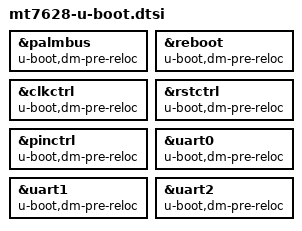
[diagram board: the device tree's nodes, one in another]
// SPDX-License-Identifier: GPL-2.0
/*
 * Copyright (C) 2020 MediaTek Inc.
 *
 * Author: Weijie Gao <weijie.gao@mediatek.com>
 */

&palmbus {
	u-boot,dm-pre-reloc;
};

&reboot {
	u-boot,dm-pre-reloc;
};

&clkctrl {
	u-boot,dm-pre-reloc;
};

&rstctrl {
	u-boot,dm-pre-reloc;
};

&pinctrl {
	u-boot,dm-pre-reloc;
};

&uart0 {
	u-boot,dm-pre-reloc;
};

&uart1 {
	u-boot,dm-pre-reloc;
};

&uart2 {
	u-boot,dm-pre-reloc;
};
